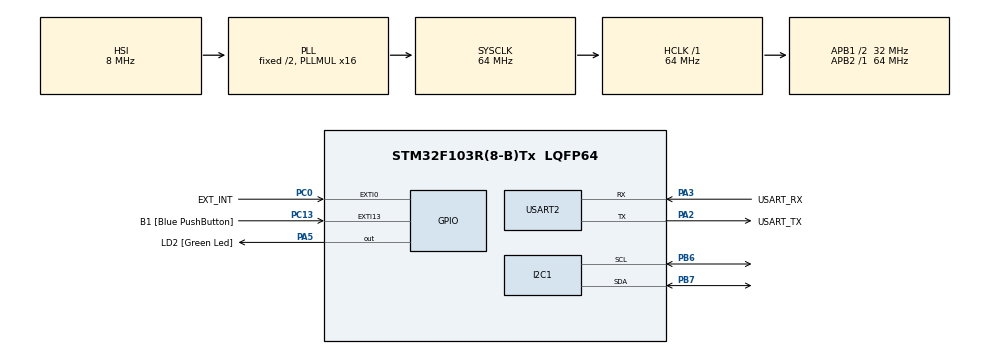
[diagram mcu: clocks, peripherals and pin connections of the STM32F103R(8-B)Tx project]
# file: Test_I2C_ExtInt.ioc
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I2C1.I2C_Mode=I2C_Fast
Mcu.Family=STM32F1
Mcu.Name=STM32F103R(8-B)Tx
Mcu.Package=LQFP64
NVIC.EXTI0_IRQn=true\:0\:0\:false\:false\:true\:true
NVIC.EXTI15_10_IRQn=true\:0\:0\:false\:false\:true\:true
NVIC.PriorityGroup=NVIC_PRIORITYGROUP_4
NVIC.USART2_IRQn=true\:0\:0\:false\:false\:true\:true
PA13.GPIO_Label=TMS
PA13.Mode=Serial_Wire
PA13.Signal=SYS_JTMS-SWDIO
PA14.GPIO_Label=TCK
PA14.Mode=Serial_Wire
PA14.Signal=SYS_JTCK-SWCLK
PA2.GPIO_Label=USART_TX
PA2.GPIO_Mode=GPIO_MODE_AF_PP
PA2.GPIO_PuPd=GPIO_NOPULL
PA2.GPIO_Speed=GPIO_SPEED_FREQ_LOW
PA2.Mode=Asynchronous
PA2.Signal=USART2_TX
PA3.GPIO_Label=USART_RX
PA3.GPIO_Mode=GPIO_MODE_AF_PP
PA3.GPIO_PuPd=GPIO_NOPULL
PA3.GPIO_Speed=GPIO_SPEED_FREQ_LOW
PA3.Mode=Asynchronous
PA3.Signal=USART2_RX
PA5.GPIO_Label=LD2 [Green Led]
PA5.GPIO_ModeDefaultOutputPP=GPIO_MODE_OUTPUT_PP
PA5.GPIO_PuPd=GPIO_NOPULL
PA5.GPIO_Speed=GPIO_SPEED_FREQ_LOW
PA5.PinState=GPIO_PIN_RESET
PA5.Signal=GPIO_Output
PB3.GPIO_Label=SWO
PB3.Signal=SYS_JTDO-TRACESWO
PB6.Mode=I2C
PB6.Signal=I2C1_SCL
PB7.Mode=I2C
PB7.Signal=I2C1_SDA
PC0.GPIO_Label=EXT_INT
PC0.GPIO_ModeDefaultEXTI=GPIO_MODE_IT_RISING_FALLING
PC0.GPIO_PuPd=GPIO_PULLDOWN
PC0.Signal=GPXTI0
PC13-TAMPER-RTC.GPIO_Label=B1 [Blue PushButton]
PC13-TAMPER-RTC.GPIO_ModeDefaultEXTI=GPIO_MODE_IT_RISING_FALLING
PC13-TAMPER-RTC.GPIO_PuPd=GPIO_PULLDOWN
PC13-TAMPER-RTC.Signal=GPXTI13
PC14-OSC32_IN.Mode=LSE-External-Oscillator
PC14-OSC32_IN.Signal=RCC_OSC32_IN
PC15-OSC32_OUT.Mode=LSE-External-Oscillator
PC15-OSC32_OUT.Signal=RCC_OSC32_OUT
PD0-OSC_IN.Mode=HSE-External-Clock-Source
PD0-OSC_IN.Signal=RCC_OSC_IN
PD1-OSC_OUT.Mode=HSE-External-Clock-Source
PD1-OSC_OUT.Signal=RCC_OSC_OUT
ProjectManager.HeapSize=0x200
ProjectManager.StackSize=0x400
ProjectManager.TargetToolchain=MDK-ARM V5
RCC.AHBFreq_Value=64000000
RCC.APB1CLKDivider=RCC_HCLK_DIV2
RCC.APB1Freq_Value=32000000
RCC.APB1TimFreq_Value=64000000
RCC.APB2Freq_Value=64000000
RCC.APB2TimFreq_Value=64000000
RCC.HCLKFreq_Value=64000000
RCC.PLLMUL=RCC_PLL_MUL16
RCC.RTCClockSelection=RCC_RTCCLKSOURCE_LSE
RCC.SYSCLKFreq_VALUE=64000000
RCC.SYSCLKSource=RCC_SYSCLKSOURCE_PLLCLK
RCC.USBFreq_Value=64000000
USART2.VirtualMode=VM_ASYNC
board=NUCLEO-F103RB

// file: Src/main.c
#include "main.h"
#include "lsm6ds33.h"

I2C_HandleTypeDef hi2c1;

UART_HandleTypeDef huart2;

void SystemClock_Config(void);
static void MX_GPIO_Init(void);
static void MX_USART2_UART_Init(void);
static void MX_I2C1_Init(void);

int main(void)
{

  /* MCU Configuration--------------------------------------------------------*/

  /* Reset of all peripherals, Initializes the Flash interface and the Systick. */
  HAL_Init();

  /* Configure the system clock */
  SystemClock_Config();

  /* Initialize all configured peripherals */
  MX_GPIO_Init();
  MX_USART2_UART_Init();
  MX_I2C1_Init();

  /* Infinite loop */
  while (1)
  {

  }
}

void SystemClock_Config(void)
{
  RCC_OscInitTypeDef RCC_OscInitStruct = {0};
  RCC_ClkInitTypeDef RCC_ClkInitStruct = {0};

  /**Initializes the CPU, AHB and APB busses clocks
  */
  RCC_OscInitStruct.OscillatorType = RCC_OSCILLATORTYPE_HSI;
  RCC_OscInitStruct.HSIState = RCC_HSI_ON;
  RCC_OscInitStruct.HSICalibrationValue = RCC_HSICALIBRATION_DEFAULT;
  RCC_OscInitStruct.PLL.PLLState = RCC_PLL_ON;
  RCC_OscInitStruct.PLL.PLLSource = RCC_PLLSOURCE_HSI_DIV2;
  RCC_OscInitStruct.PLL.PLLMUL = RCC_PLL_MUL16;
  if (HAL_RCC_OscConfig(&RCC_OscInitStruct) != HAL_OK)
  {
    Error_Handler();
  }
  /**Initializes the CPU, AHB and APB busses clocks
  */
  RCC_ClkInitStruct.ClockType = RCC_CLOCKTYPE_HCLK|RCC_CLOCKTYPE_SYSCLK
                              |RCC_CLOCKTYPE_PCLK1|RCC_CLOCKTYPE_PCLK2;
  RCC_ClkInitStruct.SYSCLKSource = RCC_SYSCLKSOURCE_PLLCLK;
  RCC_ClkInitStruct.AHBCLKDivider = RCC_SYSCLK_DIV1;
  RCC_ClkInitStruct.APB1CLKDivider = RCC_HCLK_DIV2;
  RCC_ClkInitStruct.APB2CLKDivider = RCC_HCLK_DIV1;

  if (HAL_RCC_ClockConfig(&RCC_ClkInitStruct, FLASH_LATENCY_2) != HAL_OK)
  {
    Error_Handler();
  }
}

static void MX_I2C1_Init(void)
{

  hi2c1.Instance = I2C1;
  hi2c1.Init.ClockSpeed = 400000;
  hi2c1.Init.DutyCycle = I2C_DUTYCYCLE_2;
  hi2c1.Init.OwnAddress1 = 0;
  hi2c1.Init.AddressingMode = I2C_ADDRESSINGMODE_7BIT;
  hi2c1.Init.DualAddressMode = I2C_DUALADDRESS_DISABLE;
  hi2c1.Init.OwnAddress2 = 0;
  hi2c1.Init.GeneralCallMode = I2C_GENERALCALL_DISABLE;
  hi2c1.Init.NoStretchMode = I2C_NOSTRETCH_DISABLE;
  if (HAL_I2C_Init(&hi2c1) != HAL_OK)
  {
    Error_Handler();
  }
  /* USER CODE BEGIN I2C1_Init 2 */
	lsm6ds33_inactivity();
	//lsm6ds33_init();
  /* USER CODE END I2C1_Init 2 */

}

static void MX_USART2_UART_Init(void)
{

  huart2.Instance = USART2;
  huart2.Init.BaudRate = 115200;
  huart2.Init.WordLength = UART_WORDLENGTH_8B;
  huart2.Init.StopBits = UART_STOPBITS_1;
  huart2.Init.Parity = UART_PARITY_NONE;
  huart2.Init.Mode = UART_MODE_TX_RX;
  huart2.Init.HwFlowCtl = UART_HWCONTROL_NONE;
  huart2.Init.OverSampling = UART_OVERSAMPLING_16;
  if (HAL_UART_Init(&huart2) != HAL_OK)
  {
    Error_Handler();
  }

}

static void MX_GPIO_Init(void)
{
  GPIO_InitTypeDef GPIO_InitStruct = {0};

  /* GPIO Ports Clock Enable */
  __HAL_RCC_GPIOC_CLK_ENABLE();
  __HAL_RCC_GPIOD_CLK_ENABLE();
  __HAL_RCC_GPIOA_CLK_ENABLE();
  __HAL_RCC_GPIOB_CLK_ENABLE();

  /*Configure GPIO pin Output Level */
  HAL_GPIO_WritePin(LD2_GPIO_Port, LD2_Pin, GPIO_PIN_RESET);

  /*Configure GPIO pins : B1_Pin EXT_INT_Pin */
  GPIO_InitStruct.Pin = B1_Pin|EXT_INT_Pin;
  GPIO_InitStruct.Mode = GPIO_MODE_IT_RISING_FALLING;
  GPIO_InitStruct.Pull = GPIO_PULLDOWN;
  HAL_GPIO_Init(GPIOC, &GPIO_InitStruct);

  /*Configure GPIO pin : LD2_Pin */
  GPIO_InitStruct.Pin = LD2_Pin;
  GPIO_InitStruct.Mode = GPIO_MODE_OUTPUT_PP;
  GPIO_InitStruct.Pull = GPIO_NOPULL;
  GPIO_InitStruct.Speed = GPIO_SPEED_FREQ_LOW;
  HAL_GPIO_Init(LD2_GPIO_Port, &GPIO_InitStruct);

  /* EXTI interrupt init*/
  HAL_NVIC_SetPriority(EXTI0_IRQn, 0, 0);
  HAL_NVIC_EnableIRQ(EXTI0_IRQn);

  HAL_NVIC_SetPriority(EXTI15_10_IRQn, 0, 0);
  HAL_NVIC_EnableIRQ(EXTI15_10_IRQn);

}

void Error_Handler(void)
{
}

/************************ (C) COPYRIGHT STMicroelectronics *****END OF FILE****/
